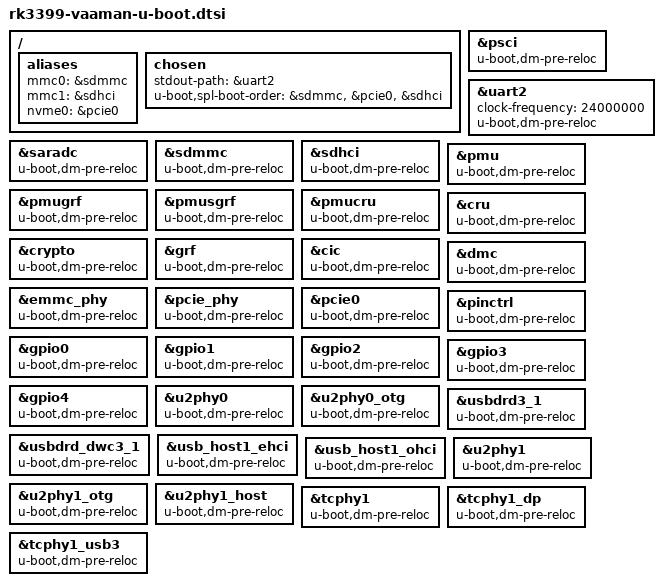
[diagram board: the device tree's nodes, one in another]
// SPDX-License-Identifier: (GPL-2.0+ OR MIT)
/*
 * Copyright (C) 2023 Vicharak Computers LLP
 */

/ {
	aliases {
		mmc0 = &sdmmc;
		mmc1 = &sdhci;
		nvme0 = &pcie0;
	};

	chosen {
		stdout-path = &uart2;
		u-boot,spl-boot-order = &sdmmc, &pcie0, &sdhci;
	};
};

&psci {
	u-boot,dm-pre-reloc;
	status = "okay";
};

&uart2 {
	clock-frequency = <24000000>;
	u-boot,dm-pre-reloc;
};

&saradc {
	u-boot,dm-pre-reloc;
};

&sdmmc {
	u-boot,dm-pre-reloc;
};

&sdhci {
	u-boot,dm-pre-reloc;
};

&pmu {
	u-boot,dm-pre-reloc;
};

&pmugrf {
	u-boot,dm-pre-reloc;
};

&pmusgrf {
	u-boot,dm-pre-reloc;
};

&pmucru {
	u-boot,dm-pre-reloc;
};

&cru {
	u-boot,dm-pre-reloc;
};

&crypto {
	u-boot,dm-pre-reloc;
};

&grf {
	u-boot,dm-pre-reloc;
};

&cic {
	u-boot,dm-pre-reloc;
};

&dmc {
	u-boot,dm-pre-reloc;
};

&emmc_phy {
	u-boot,dm-pre-reloc;
};

&pcie_phy {
	u-boot,dm-pre-reloc;
};

&pcie0 {
	u-boot,dm-pre-reloc;
};

&pinctrl {
	u-boot,dm-pre-reloc;
};

&gpio0 {
	u-boot,dm-pre-reloc;
};

&gpio1 {
	u-boot,dm-pre-reloc;
};

&gpio2 {
	u-boot,dm-pre-reloc;
};

&gpio3 {
	u-boot,dm-pre-reloc;
};

&gpio4 {
	u-boot,dm-pre-reloc;
};

&u2phy0 {
	u-boot,dm-pre-reloc;
	status = "okay";
};

&u2phy0_otg {
	u-boot,dm-pre-reloc;
	status = "okay";
};

&usbdrd3_1 {
	u-boot,dm-pre-reloc;
};

&usbdrd_dwc3_1 {
	u-boot,dm-pre-reloc;
};

&usb_host1_ehci {
	u-boot,dm-pre-reloc;
};

&usb_host1_ohci {
	u-boot,dm-pre-reloc;
};

&u2phy1 {
	u-boot,dm-pre-reloc;
};

&u2phy1_otg {
	u-boot,dm-pre-reloc;
};

&u2phy1_host {
	u-boot,dm-pre-reloc;
};

&tcphy1 {
	u-boot,dm-pre-reloc;
};

&tcphy1_dp {
	u-boot,dm-pre-reloc;
};

&tcphy1_usb3 {
	u-boot,dm-pre-reloc;
};
